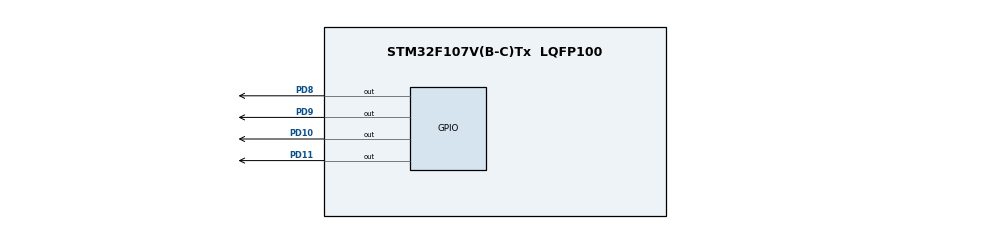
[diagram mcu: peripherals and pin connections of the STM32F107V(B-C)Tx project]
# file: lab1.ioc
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Mcu.Family=STM32F1
Mcu.Name=STM32F107V(B-C)Tx
Mcu.Package=LQFP100
NVIC.PriorityGroup=NVIC_PRIORITYGROUP_4
PA13.Mode=Serial_Wire
PA13.Signal=SYS_JTMS-SWDIO
PA14.Mode=Serial_Wire
PA14.Signal=SYS_JTCK-SWCLK
PD10.Signal=GPIO_Output
PD11.Signal=GPIO_Output
PD8.Signal=GPIO_Output
PD9.Signal=GPIO_Output
ProjectManager.HeapSize=0x200
ProjectManager.StackSize=0x400
ProjectManager.TargetToolchain=MDK-ARM V5.32
RCC.USBFreq_Value=10666666.666666666
board=custom

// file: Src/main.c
/* USER CODE BEGIN Header */
/**
  ******************************************************************************
  * @file           : main.c
  * @brief          : Main program body
  ******************************************************************************
  * @attention
  *
  * Copyright (c) 2022 STMicroelectronics.
  * All rights reserved.
  *
  * This software is licensed under terms that can be found in the LICENSE file
  * in the root directory of this software component.
  * If no LICENSE file comes with this software, it is provided AS-IS.
  *
  ******************************************************************************
  */
/* USER CODE END Header */
#include "main.h"

void SystemClock_Config(void);
static void MX_GPIO_Init(void);

int main(void)
{

  /* MCU Configuration--------------------------------------------------------*/

  /* Reset of all peripherals, Initializes the Flash interface and the Systick. */
  HAL_Init();

  /* Configure the system clock */
  SystemClock_Config();

  /* Initialize all configured peripherals */
  MX_GPIO_Init();
	uint16_t array[]= {GPIO_PIN_8, GPIO_PIN_9,GPIO_PIN_10,GPIO_PIN_11};

  /* Infinite loop */
  /* USER CODE BEGIN WHILE */
  while (1)
  {
		for(int i =0; i<17;i++){
			if ((i%2>0)){  HAL_GPIO_WritePin(GPIOD, array[0], GPIO_PIN_SET); }else { HAL_GPIO_WritePin(GPIOD, array[0], GPIO_PIN_RESET);}
			if ((i%4>1)){  HAL_GPIO_WritePin(GPIOD, array[1], GPIO_PIN_SET); }else { HAL_GPIO_WritePin(GPIOD, array[1], GPIO_PIN_RESET);}
			if ((i%8>3)){  HAL_GPIO_WritePin(GPIOD, array[2], GPIO_PIN_SET); }else { HAL_GPIO_WritePin(GPIOD, array[2], GPIO_PIN_RESET);}
			if ((i%16>7)){  HAL_GPIO_WritePin(GPIOD, array[3], GPIO_PIN_SET); }else { HAL_GPIO_WritePin(GPIOD, array[3], GPIO_PIN_RESET);}
			HAL_Delay(500);
		}

    /* USER CODE END WHILE */

  }
}

void SystemClock_Config(void)
{
  RCC_OscInitTypeDef RCC_OscInitStruct = {0};
  RCC_ClkInitTypeDef RCC_ClkInitStruct = {0};

  /** Initializes the RCC Oscillators according to the specified parameters
  * in the RCC_OscInitTypeDef structure.
  */
  RCC_OscInitStruct.OscillatorType = RCC_OSCILLATORTYPE_HSI;
  RCC_OscInitStruct.HSIState = RCC_HSI_ON;
  RCC_OscInitStruct.HSICalibrationValue = RCC_HSICALIBRATION_DEFAULT;
  RCC_OscInitStruct.PLL.PLLState = RCC_PLL_NONE;
  RCC_OscInitStruct.PLL2.PLL2State = RCC_PLL_NONE;
  if (HAL_RCC_OscConfig(&RCC_OscInitStruct) != HAL_OK)
  {
    Error_Handler();
  }
  /** Initializes the CPU, AHB and APB buses clocks
  */
  RCC_ClkInitStruct.ClockType = RCC_CLOCKTYPE_HCLK|RCC_CLOCKTYPE_SYSCLK
                              |RCC_CLOCKTYPE_PCLK1|RCC_CLOCKTYPE_PCLK2;
  RCC_ClkInitStruct.SYSCLKSource = RCC_SYSCLKSOURCE_HSI;
  RCC_ClkInitStruct.AHBCLKDivider = RCC_SYSCLK_DIV1;
  RCC_ClkInitStruct.APB1CLKDivider = RCC_HCLK_DIV1;
  RCC_ClkInitStruct.APB2CLKDivider = RCC_HCLK_DIV1;

  if (HAL_RCC_ClockConfig(&RCC_ClkInitStruct, FLASH_LATENCY_0) != HAL_OK)
  {
    Error_Handler();
  }
  /** Configure the Systick interrupt time
  */
  __HAL_RCC_PLLI2S_ENABLE();
}

static void MX_GPIO_Init(void)
{
  GPIO_InitTypeDef GPIO_InitStruct = {0};

  /* GPIO Ports Clock Enable */
  __HAL_RCC_GPIOD_CLK_ENABLE();
  __HAL_RCC_GPIOA_CLK_ENABLE();

  /*Configure GPIO pin Output Level */
  HAL_GPIO_WritePin(GPIOD, GPIO_PIN_8|GPIO_PIN_9|GPIO_PIN_10|GPIO_PIN_11, GPIO_PIN_RESET);

  /*Configure GPIO pins : PD8 PD9 PD10 PD11 */
  GPIO_InitStruct.Pin = GPIO_PIN_8|GPIO_PIN_9|GPIO_PIN_10|GPIO_PIN_11;
  GPIO_InitStruct.Mode = GPIO_MODE_OUTPUT_PP;
  GPIO_InitStruct.Pull = GPIO_NOPULL;
  GPIO_InitStruct.Speed = GPIO_SPEED_FREQ_LOW;
  HAL_GPIO_Init(GPIOD, &GPIO_InitStruct);

}

void Error_Handler(void)
{
  /* USER CODE BEGIN Error_Handler_Debug */
  /* User can add his own implementation to report the HAL error return state */
  __disable_irq();
  while (1)
  {
			HAL_GPIO_TogglePin(GPIOD, GPIO_PIN_8);
		   HAL_Delay(1000);
  }
  /* USER CODE END Error_Handler_Debug */
}
